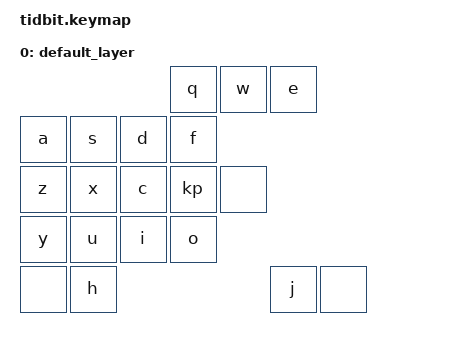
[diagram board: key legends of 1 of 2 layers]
/*
 * Copyright (c) 2020 The ZMK Contributors
 *
 * SPDX-License-Identifier: MIT
 */

#include <behaviors.dtsi>
#include <dt-bindings/zmk/bt.h>
#include <dt-bindings/zmk/outputs.h>
#include <dt-bindings/zmk/keys.h>

&encoder_1_top_row {
	status = "okay";
};

/ {
	sensors {
		compatible = "zmk,keymap-sensors";
		sensors = <&encoder_1_top_row>;
	};

	keymap {
		compatible = "zmk,keymap";

		default_layer {
			bindings = <
								&kp q  &kp w &kp e
				&kp a &kp s &kp d &kp f
				&kp z &kp x &kp c &kp &none
				&kp y &kp u &kp i &kp o
				&none           &kp h &kp j      &none
			>;

			sensor-bindings = <&inc_dec_kp C_VOLUME_UP C_VOLUME_DOWN>;
		};

		 func_layer {
			 bindings = <
								&none           &reset          &bootloader
				&out OUT_TOG    &out OUT_USB    &out OUT_BLE    &none
				&bt BT_SEL 0    &bt BT_PRV      &bt BT_NXT      &bt BT_CLR
				&bt BT_SEL 1    &bt BT_SEL 2    &bt BT_SEL 3    &tog 0
				&kp C_MUTE      &none           &none           &none
			 >;

			 sensor-bindings = <&inc_dec_kp C_VOLUME_UP C_VOLUME_DOWN>;
		 };
	};
};
